# R7FA6M2AF register map
Vendor: Renesas; Series: RA6; File version: 1.2
CPU: CM4 r0p1, little endian, MPU, FPU, VTOR, 4 interrupt priority bits
Registers are 8-bit, read-write, reset 0x0 unless marked. A register's access mark holds for its fields unless they carry their own. Offsets are from the block's base; [hi:lo] are bit positions; {n}, {i} and the like mark numbered series; 'fields as' and 'values as' point back to an identical list.

## SMPU — Bus Slave MPU
Base 0x40000C00
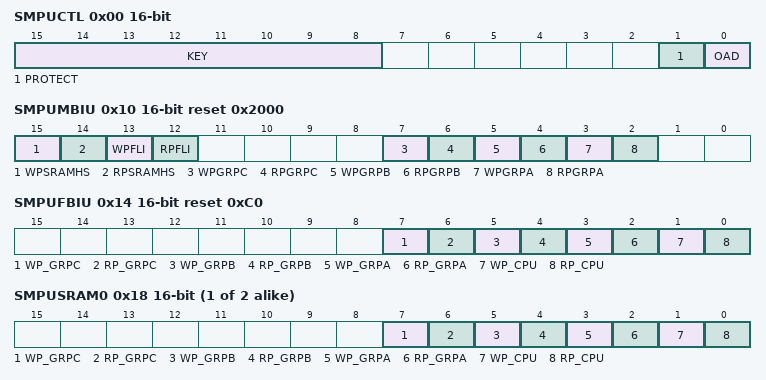
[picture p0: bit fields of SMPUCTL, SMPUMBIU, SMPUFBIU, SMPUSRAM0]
0x00 SMPUCTL 16-bit — Slave MPU Control Register
  [15:8] KEY wo — Key Code This bit is used to enable or disable rewriting of the PROTECT and OAD bit.
  [1] PROTECT — Protection of register
  [0] OAD — Master Group enable
0x10 SMPUMBIU 16-bit reset 0x2000 — Access Control Register for MBIU
  [15] WPSRAMHS — SRAMHS Write Protection
  [14] RPSRAMHS — SRAMHS Read Protection
  [13] WPFLI — Code Flash Memory Write Protection (Note: This bit is read as 1. The write value should be 1.)
  [12] RPFLI — Code Flash Memory Read Protection
  [7] WPGRPC — Master Group C Write protection
  [6] RPGRPC — Master Group C Read protection
  [5] WPGRPB — Master Group B Write protection
  [4] RPGRPB — Master Group B Read protection
  [3] WPGRPA — Master Group A Write protection
  [2] RPGRPA — Master Group A Read protection
0x14 SMPUFBIU 16-bit reset 0xC0 — Access Control Register for FBIU
  [7] WP_GRPC — Master Group C Write protection
  [6] RP_GRPC — Master Group C Read protection
  [5] WP_GRPB — Master Group B Write protection
  [4] RP_GRPB — Master Group B Read protection
  [3] WP_GRPA — Master Group A Write protection
  [2] RP_GRPA — Master Group A Read protection
  [1] WP_CPU — CPU Write protection
  [0] RP_CPU — CPU Read protection
{0x18+4i} SMPUSRAM{i} (i=0..1) 16-bit — Access Control Register for SRAM{i}
  fields as SMPUFBIU
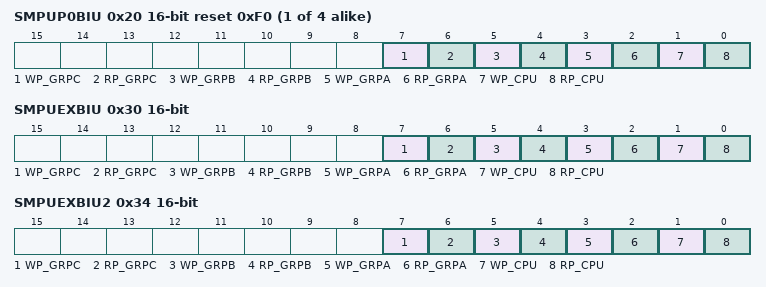
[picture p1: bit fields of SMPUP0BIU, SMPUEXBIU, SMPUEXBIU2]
0x20 SMPUP{x}BIU (x=0,2,6,7; step 0x4) 16-bit reset 0xF0 — Access Control Register for P{x}BIU
  fields as SMPUFBIU
0x30 SMPUEXBIU 16-bit — Access Control Register for EXBIU
  fields as SMPUFBIU
0x34 SMPUEXBIU2 16-bit — Access Control Register for EXBIU2
  fields as SMPUFBIU

## SPMON — CPU Stack Pointer Monitor
Base 0x40000D00
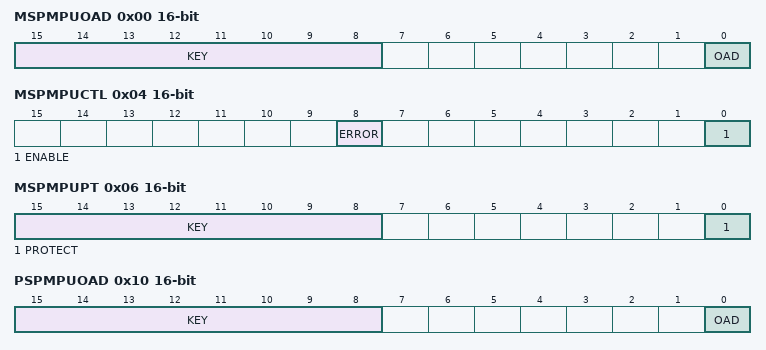
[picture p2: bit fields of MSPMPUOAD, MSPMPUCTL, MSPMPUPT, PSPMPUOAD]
0x00 MSPMPUOAD 16-bit — Stack Pointer Monitor Operation After Detection Register
  [15:8] KEY wo — Write Keyword The data written to these bits are not stored.
  [0] OAD — Operation after detection
0x04 MSPMPUCTL 16-bit — Stack Pointer Monitor Access Control Register
  [8] ERROR ro — SP_main monitor error flag
  [0] ENABLE — SP_main monitor enable
0x06 MSPMPUPT 16-bit — Stack Pointer Monitor Protection Register
  [15:8] KEY wo — Write Keyword The data written to these bits are not stored.
  [0] PROTECT — Protection of register (MSPMPUAC, MSPMPUSA and MSPMPUSE)
0x08 MSPMPUSA 32-bit (reset mask 0x3) — Main Stack Pointer Monitor Start Address Register
  [31:2] MSPMPUSA range 0x1FF00000..0x200FFFFC — Region start address register Address where the region starts, for use in region determination.NOTE: Range: 0x1FF00000-0x200FFFFC The low,order 2 bits are fixed to 0.
0x0C MSPMPUEA 32-bit reset 0x3 (reset mask 0x3) — Main Stack Pointer Monitor End Address Register
  [31:2] MSPMPUEA range 0x1FF00003..0x200FFFFF — Region end address register Address where the region starts, for use in region determination.NOTE: Range: 0x1FF00003-0x200FFFFF The low,order 2 bits are fixed to 1.
0x10 PSPMPUOAD 16-bit — Stack Pointer Monitor Operation After Detection Register
  fields as MSPMPUOAD
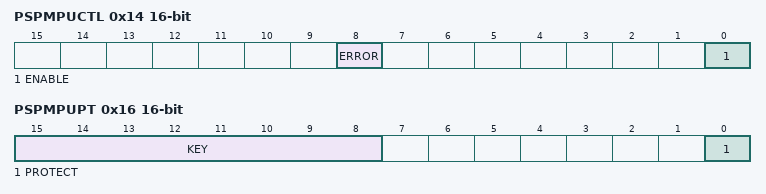
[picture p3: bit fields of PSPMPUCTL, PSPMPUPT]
0x14 PSPMPUCTL 16-bit (reset mask 0xFEFF) — Stack Pointer Monitor Access Control Register
  [8] ERROR ro — SP_process monitor error flag
  [0] ENABLE — SP_process monitor enable
0x16 PSPMPUPT 16-bit — Stack Pointer Monitor Protection Register
  [15:8] KEY wo — Write Keyword The data written to these bits are not stored.
  [0] PROTECT — Protection of register (PSPMPUAC, PSPMPUSA and PSPMPUSE)
0x18 PSPMPUSA 32-bit (reset mask 0x3) — Process Stack Pointer Monitor Start Address Register
  [31:2] PSPMPUSA range 0x1FF00000..0x200FFFFC — Region start address register Address where the region starts, for use in region determination.NOTE: Range: 0x1FF00000-0x200FFFFC The low,order 2 bits are fixed to 0.
0x1C PSPMPUEA 32-bit reset 0x3 (reset mask 0x3) — Process Stack Pointer Monitor End Address Register
  [31:2] PSPMPUEA range 0x1FF00003..0x200FFFFF — Region end address register Address where the region starts, for use in region determination.NOTE: Range: 0x1FF00003-0x200FFFFF The low,order 2 bits are fixed to 1.
